# STM32WBA52 register map
File version: 1.3
CPU: CM33 r0p1, little endian, MPU, FPU, 4 interrupt priority bits
Registers are 32-bit, read-write, reset 0x0 unless marked. A register's access mark holds for its fields unless they carry their own. Offsets are from the block's base; [hi:lo] are bit positions; {n}, {i} and the like mark numbered series; 'fields as' and 'values as' point back to an identical list.

## FLASH — Embedded Flash memory
Base 0x40022000
Same registers: SEC_FLASH 0x50022000
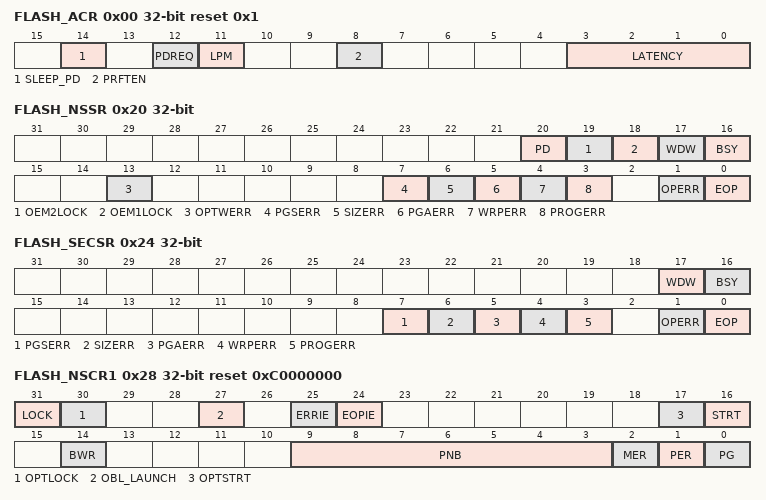
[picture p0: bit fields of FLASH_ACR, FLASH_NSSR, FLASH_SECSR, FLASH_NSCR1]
0x00 FLASH_ACR reset 0x1 — FLASH access control register
  [14] SLEEP_PD — Flash memory power-down mode during Sleep mode This bit determines whether the Flash memory is in power-down mode or Idle mode when the device is in Sleep mode. Access to the bit can be secured by PWR LPMSEC. When secure, a non-secure read/write access is RAZ/WI. It does not generate an illegal access interrupt. This bit can be protected against unprivileged access when secure with FLASH SPRIV or when non-secure with FLASH NSPRIV. The Flash must not be put in power-down while a program or an erase operation is ongoing.
    0=Flash in Idle mode during Sleep mode; 1=Flash in power-down mode during Sleep mode
  [12] PDREQ — Flash power-down mode request This bit requests Flash to enter power-down mode. When Flash enters power-down mode, this bit is cleared by hardware and the PDKEYR is locked. This bit is write-protected with FLASH_PDKEYR. Access to the bit can be secured by PWR LPMSEC. When secure, a non-secure read/write access is RAZ/WI. It does not generate an illegal access interrupt. This bit can be protected against unprivileged access when secure with FLASH SPRIV or when non-secure with FLASH NSPRIV.
    0=No request for Flash to enter power-down mode; 1=Flash requested to enter power-down mode
  [11] LPM — Low-power read mode This bit puts the Flash memory in low-power read mode. Access to the bit can be secured by PWR LPMSEC. When secure, a non-secure read/write access is RAZ/WI. It does not generate an illegal access interrupt. This bit can be protected against unprivileged access when secure with FLASH SPRIV or when non-secure with FLASH NSPRIV. This bit can't be written when a Flash program or erase operation is busy (BSY = 1) or when the write buffer is not empty (WDW = 1). Changing this bit while a Flash program or erase operation is busy (BSY = 1) is rejected.
    0=Flash not in low-power read mode; 1=Flash in low-power read mode
  [8] PRFTEN — Prefetch enable This bit enables the prefetch buffer in the embedded Flash memory. This bit can be protected against unprivileged access by FLASH NSPRIV.
    0=Prefetch disabled; 1=Prefetch enabled
  [3:0] LATENCY — Latency These bits represent the ratio between the AHB hclk1 clock period and the Flash memory access time. Access to the bit can be secured by RCC SYSCLKSEC. When secure, a non-secure read/write access is RAZ/WI. It does not generate an illegal access interrupt. This bit can be protected against unprivileged access when secure with FLASH SPRIV or when non-secure with FLASH NSPRIV. ... Note: Before entering Stop 1 mode software must set FLASH wait state latency to at least 1.
    0=Zero wait state; 1=One wait state; 2=Two wait states; 15=Fifteen wait states
0x08 FLASH_NSKEYR wo — FLASH key register
  [31:0] NSKEY — Flash memory non-secure key The following values must be written consecutively to unlock the FLASH_NSCR1 register, allowing the Flash memory non-secure programming/erasing operations: KEY1: 0x45670123 KEY2: 0xCDEF89AB
0x0C FLASH_SECKEYR wo — FLASH secure key register
  [31:0] SECKEY — Flash memory secure key The following values must be written consecutively to unlock the FLASH_SECCR1 register, allowing the Flash memory secure programming/erasing operations: KEY1: 0x45670123 KEY2: 0xCDEF89AB
0x10 FLASH_OPTKEYR wo — FLASH option key register
  [31:0] OPTKEY — Option byte key The LOCK bit in the FLASH_NSCR1 must be cleared before doing the unlock sequence for OPTLOCK bit. The following values must be written consecutively to unlock the FLASH_NSCR1.OPTSTRT and OBL_LAUNCH register bits concerning user option operations: KEY1: 0x08192A3B KEY2: 0x4C5D6E7F
0x18 FLASH_PDKEYR wo — FLASH power-down key register
  [31:0] PDKEY1 — Flash power-down key The following values must be written consecutively to unlock the PDREQ bit in FLASH_ACR: PDKEY_1: 0x04152637 PDKEY_2: 0xFAFBFCFD
0x20 FLASH_NSSR access per field (reset mask 0xFFF0FFFF) — FLASH status register
  [20] PD ro — Flash in power-down mode This bit indicates that the Flash memory is in power-down state. It is reset when Flash is in normal mode or being awaken.
  [19] OEM2LOCK ro — OEM2 key RDP lock This bit indicates that the OEM2 key read during the OBL is not virgin. When set, the OEM2 key RDP lock mechanism is active.
  [18] OEM1LOCK ro — OEM1 key RDP lock This bit indicates that the OEM1 key read during the OBL is not virgin. When set, the OEM1 key RDP lock mechanism is active.
  [17] WDW ro — Non-secure wait data to write This bit indicates that the Flash memory write buffer has been written by a secure or non-secure operation. It is set when the first data is stored in the buffer and cleared when the write is performed in the Flash memory.
  [16] BSY ro — Non-secure busy This indicates that a Flash memory secure or non-secure operation is in progress. This bit is set at the beginning of a Flash operation and reset when the operation finishes or when an error occurs.
  [13] OPTWERR rw — Option write error This bit is set by hardware when the options bytes are written with an invalid configuration or when modifying options in RDP level 2.. It is cleared by writing 1. Refer to Section7.3.10: Flash memory errors flags for full conditions of error flag setting.
  [7] PGSERR rw — Non-secure programming sequence error This bit is set by hardware when programming sequence is not correct. It is cleared by writing 1. Refer to Section7.3.10: Flash memory errors flags for full conditions of error flag setting.
  [6] SIZERR rw — Non-secure size error This bit is set by hardware when the size of the access is a byte or half-word during a non-secure program sequence. Only quad-word programming is allowed by means of successive word accesses. This bit is cleared by writing 1.
  [5] PGAERR rw — Non-secure programming alignment error This bit is set by hardware when the first word to be programmed is not aligned with a quad-word address, or the second, third or forth word does not belong to the same quad-word address. This bit is cleared by writing 1.
  [4] WRPERR rw — Non-secure write protection error This bit is set by hardware when a non-secure address to be erased/programmed belongs to a write-protected part (by WRP or HDP) of the Flash memory. This bit is cleared by writing 1. Refer to Section7.3.10: Flash memory errors flags for full conditions of error flag setting.
  [3] PROGERR rw — Non-secure programming error This bit is set by hardware when a non-secure quad-word address to be programmed contains a value different from all 1 before programming, except if the data to write is all 0. This bit is cleared by writing 1.
  [1] OPERR rw — Non-secure operation error This bit is set by hardware when a Flash memory non-secure operation (program/erase) completes unsuccessfully. This bit is set only if non-secure error interrupts are enabled (NSERRIE = 1). This bit is cleared by writing 1.
  [0] EOP rw — Non-secure end of operation This bit is set by hardware when one or more Flash memory non-secure operation (program/erase) has been completed successfully. This bit is set only if the non-secure end of operation interrupts are enabled (EOPIE = 1 in FLASH_NSCR1). This bit is cleared by writing1.
0x24 FLASH_SECSR access per field — FLASH secure status register
  [17] WDW ro — Secure wait data to write This bit indicates that the Flash memory write buffer has been written by a secure or non-secure operation. It is set when the first data is stored in the buffer and cleared when the write is performed in the Flash memory.
  [16] BSY ro — Secure busy This bit indicates that a Flash memory secure or non-secure operation is in progress. This is set on the beginning of a Flash operation and reset when the operation finishes or when an error occurs.
  [7] PGSERR rw — Secure programming sequence error This bit is set by hardware when programming sequence is not correct. It is cleared by writing 1. Refer to Section7.3.10: Flash memory errors flags for full conditions of error flag setting.
  [6] SIZERR rw — Secure size error This bit is set by hardware when the size of the access is a byte or half-word during a secure program sequence. Only quad-word programming is allowed by means of successive word accesses.This bit is cleared by writing 1.
  [5] PGAERR rw — Secure programming alignment error This bit is set by hardware when the first word to be programmed is not aligned with a quad-word address, or the second, third or forth word does not belong to the same quad-word address.This bit is cleared by writing 1.
  [4] WRPERR rw — Secure write protection error This bit is set by hardware when an secure address to be erased/programmed belongs to a write-protected part (by WRP or HDP) of the Flash memory. This bit is cleared by writing 1. Refer to Section7.3.10: Flash memory errors flags for full conditions of error flag setting.
  [3] PROGERR rw — Secure programming error This bit is set by hardware when a secure quad-word address to be programmed contains a value different from all 1 before programming, except if the data to write is all 0. This bit is cleared by writing 1.
  [1] OPERR rw — Secure operation error This bit is set by hardware when a Flash memory secure operation (program/erase) completes unsuccessfully. This bit is set only if secure error interrupts are enabled (SECERRIE = 1). This bit is cleared by writing 1.
  [0] EOP rw — Secure end of operation This bit is set by hardware when one or more Flash memory secure operation (program/erase) has been completed successfully. This bit is set only if the secure end of operation interrupts are enabled (EOPIE = 1 in FLASH_SECCR1). This bit is cleared by writing1.
0x28 FLASH_NSCR1 reset 0xC0000000 — FLASH control register
  [31] LOCK — Non-secure lock This bit is set only. When set, the FLASH_NSCR1 register write access is locked. This bit is cleared by hardware after detecting the unlock sequence in FLASH_NSKEYR. In case of an unsuccessful unlock operation, this bit remains set until the next system reset.
  [30] OPTLOCK — Option lock This bit is set only. When set, the FLASH_NSCR1.OPTSRT and OBL_LAUNCH bits concerning user options write access is locked. This bit is cleared by hardware after detecting the unlock sequence in FLASH_OPTKEYR. The FLASH_NSCR1.LOCK bit must be cleared before doing the FLASH_OPTKEYR unlock sequence. In case of an unsuccessful unlock operation, this bit remains set until the next reset.
  [27] OBL_LAUNCH — Force the option byte loading When set to 1, this bit forces the option byte reloading. This bit is cleared only when the option byte loading is complete. This bit is write-protected with OPTLOCK. Note: The LSE oscillator must be disabled, LSEON = 0 and LSERDY = 0, before starting OBL_LAUNCH.
    0=Option byte loading complete; 1=Option byte loading requested
  [25] ERRIE — Non-secure error interrupt enable This bit enables the interrupt generation when the OPERR bit in the FLASH_NSSR is set to 1.
    0=Non-secure OPERR error interrupt disabled; 1=Non-secure OPERR error interrupt enabled
  [24] EOPIE — Non-secure end of operation interrupt enable This bit enables the interrupt generation when the EOP bit in the FLASH_NSSR is set to 1.
    0=Non-secure EOP Interrupt disabled; 1=Non-secure EOP Interrupt enabled
  [17] OPTSTRT — Options modification start This bit triggers an option bytes erase and program operation when set. This bit is write-protected with OPTLOCK.. This bit is set only by software, and is cleared when the BSY bit is cleared in FLASH_NSSR.
  [16] STRT — Non-secure operation start This bit triggers a non-secure erase operation when set. If MER and PER bits are reset and the STRT bit is set, the PGSERR bit in FLASH_NSSR is set (this condition is forbidden). This bit is set only by software and is cleared when the BSY bit is cleared in FLASH_NSSR.
  [14] BWR — Non-secure burst write programming mode When set, this bit selects the burst write programming mode.
  [9:3] PNB — Non-secure page number selection These bits select the page to erase. ... Note that bit 9 is reserved on STM32WBA5xEx devices.
    0=page 0; 1=page 1; 127=page 127
  [2] MER — Non-secure Flash mass erase This bit triggers the Flash non-secure mass erase (all Flash user pages) when set.
  [1] PER — Non-secure page erase
    0=Non-secure page erase disabled; 1=Non-secure page erase enabled
  [0] PG — Non-secure programming
    0=Non-secure Flash programming disabled; 1=Non-secure Flash programming enabled
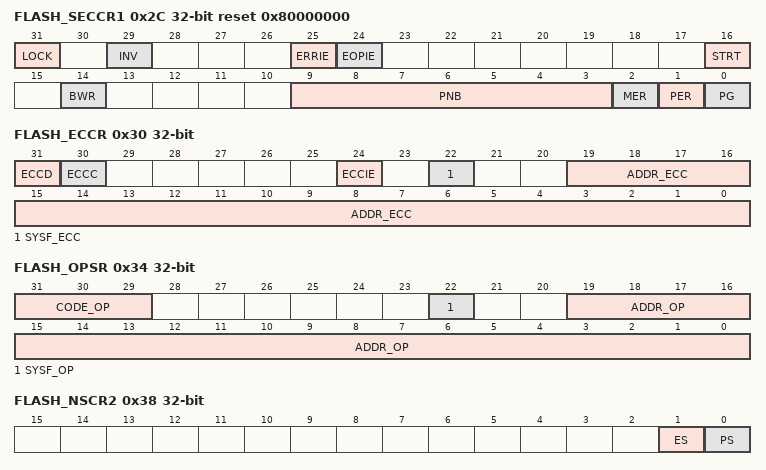
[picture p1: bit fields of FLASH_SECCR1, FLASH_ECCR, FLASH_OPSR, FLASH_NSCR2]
0x2C FLASH_SECCR1 reset 0x80000000 — FLASH secure control register
  [31] LOCK — Secure lock This bit is set only. When set, the FLASH_SECCR1 register is locked. It is cleared by hardware after detecting the unlock sequence in FLASH_SECKEYR register. In case of an unsuccessful unlock operation, this bit remains set until the next system reset.
  [29] INV — Flash memory security state invert This bit inverts the Flash memory security state.
  [25] ERRIE — Secure error interrupt enable This bit enables the interrupt generation when the OPERR bit in FLASH_SECSR is set to 1.
    0=Secure OPERR error interrupt disabled; 1=Secure OPERR error interrupt enabled
  [24] EOPIE — Secure End of operation interrupt enable This bit enables the interrupt generation when the EOP bit in FLASH_SECSR is set to 1.
    0=Secure EOP Interrupt disabled; 1=Secure EOP Interrupt enabled
  [16] STRT — Secure start This bit triggers a secure erase operation when set. If MER and PER bits are reset and the STRT bit is set, the PGSERR in the FLASH_SECSR is set (this condition is forbidden). This bit is set only by software and is cleared when the BSY bit is cleared in FLASH_SECSR.
  [14] BWR — Secure burst write programming mode When set, this bit selects the burst write programming mode.
  [9:3] PNB — Secure page number selection These bits select the page to erase: ... Note that bit 9 is reserved on STM32WBA5xEx devices.
    0=page 0; 1=page 1; 127=page 127
  [2] MER — Secure Flash mass erase This bit triggers the Flash secure mass erase (all Flash user pages) when set.
  [1] PER — Secure page erase
    0=Secure page erase disabled; 1=Secure page erase enabled
  [0] PG — Secure programming
    0=Secure Flash programming disabled; 1=Secure Flash programming enabled
0x30 FLASH_ECCR access per field — FLASH ECC register
  [31] ECCD rw — ECC detection This bit is set by hardware when two ECC errors have been detected (only if ECCC and ECCD were previously cleared). When this bit is set, a NMI is generated. This bit is cleared by writing 1.
  [30] ECCC rw — ECC correction This bit is set by hardware when one ECC error has been detected and corrected (only if ECCC and ECCD were previously cleared). An interrupt is generated if ECCIE is set. This bit is cleared by writing 1.
  [24] ECCIE rw — ECC correction interrupt enable This bit enables the interrupt generation when the ECCC bit in the FLASH_ECCR register is set.
    0=ECCC interrupt disabled; 1=ECCC interrupt enabled
  [22] SYSF_ECC ro — System Flash memory ECC fail This bit indicates that the ECC error correction or double ECC error detection is located in the system Flash memory.
  [19:0] ADDR_ECC ro — ECC fail address This field indicates which address is concerned by the ECC error correction or by the double ECC error detection. The address is given relative to Flash base address, from offset 0x00000 to 0xFFFF0. Note that bit 19 is reserved on STM32WBAxEx devices.
0x34 FLASH_OPSR ro (reset mask 0xF000000) — FLASH operation status register
  [31:29] CODE_OP — Flash memory operation code This field indicates which Flash memory operation has been interrupted by a system reset:
    0=No Flash operation interrupted by previous reset; 1=Single write operation interrupted; 2=Burst write operation interrupted; 3=Page erase operation interrupted; 5=Mass erase operation interrupted; 6=Option change operation interrupted
  [22] SYSF_OP — Operation in system Flash memory interrupted This bit indicates that the reset occurred during an operation in the system Flash memory.
  [19:0] ADDR_OP — Interrupted operation address This field indicates which address in the Flash memory was accessed when reset occurred. The address is given relative to the Flash base address, from offset 0x00000 to 0xFFFF0. Note that bit 19 is reserved on STM32WBAxEx devices.
0x38 FLASH_NSCR2 — FLASH control 2 register
  [1] ES — Erase suspend request
    0=erase suspend disabled; 1=erase suspend requested (enabled)
  [0] PS — Program suspend request
    0=program suspend disabled; 1=program suspend requested (enabled)
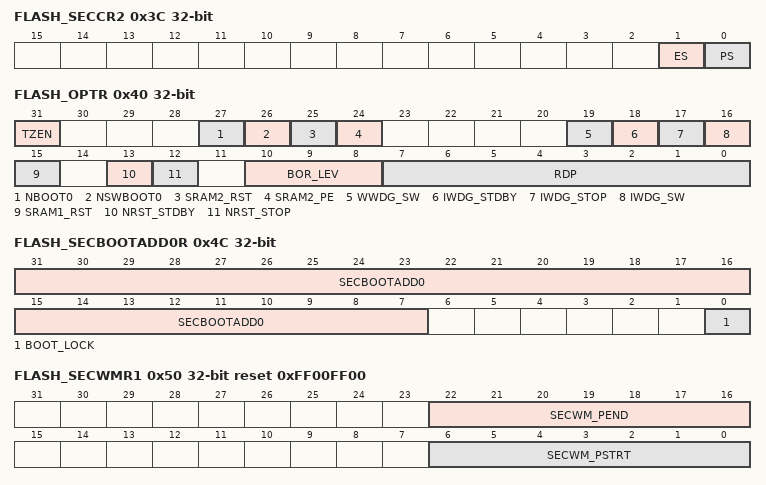
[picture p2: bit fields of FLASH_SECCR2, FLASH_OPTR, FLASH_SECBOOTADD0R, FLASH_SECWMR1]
0x3C FLASH_SECCR2 — FLASH secure control 2 register
  fields as FLASH_NSCR2
0x40 FLASH_OPTR reset not defined — FLASH option register
  [31] TZEN — Global TrustZone security enable
    0=Global TrustZone security disabled; 1=Global TrustZone security enabled
  [27] NBOOT0 — NBOOT0 option bit
    0=NBOOT0 = 0; 1=NBOOT0 = 1
  [26] NSWBOOT0 — Software BOOT0
    0=BOOT0 taken from the option bit NBOOT0; 1=BOOT0 taken from PH3/BOOT0 pin
  [25] SRAM2_RST — SRAM2 erase when system reset
    0=SRAM2 erased when a system reset occurs; 1=SRAM2 not erased when a system reset occurs
  [24] SRAM2_PE — SRAM2 parity check enable
    0=SRAM2 parity check enabled; 1=SRAM2 parity check disabled
  [19] WWDG_SW — Window watchdog selection
    0=Hardware window watchdog selected; 1=Software window watchdog selected
  [18] IWDG_STDBY — Independent watchdog counter freeze in Standby mode
    0=Independent watchdog counter frozen in Standby mode; 1=Independent watchdog counter running in Standby mode
  [17] IWDG_STOP — Independent watchdog counter freeze in Stop mode
    0=Independent watchdog counter frozen in Stop mode; 1=Independent watchdog counter running in Stop mode
  [16] IWDG_SW — Independent watchdog enable selection
    0=Hardware mode, independent watchdog started automatically be hardware on reset selected; 1=Software mode, independent watchdog started by software command selected
  [15] SRAM1_RST — SRAM1 erase upon system reset
    0=SRAM1erased when a system reset occurs; 1=SRAM1 not erased when a system reset occurs
  [13] NRST_STDBY — Reset generation in Standby mode
    0=Reset generated when entering the Standby mode; 1=No reset generated when entering the Standby mode
  [12] NRST_STOP — Reset generation in Stop mode
    0=Reset generated when entering the Stop mode; 1=No reset generated when entering the Stop mode
  [10:8] BOR_LEV — BOR reset level These bits contain the VsubDD/sub supply level threshold that activates/releases the reset.
    0=BOR level 0 (reset level threshold around 1.7V); 1=BOR level 1 (reset level threshold around 2.0V); 2=BOR level 2 (reset level threshold around 2.2V); 3=BOR level 3 (reset level threshold around 2.5V); 4=BOR level 4 (reset level threshold around 2.8V)
  [7:0] RDP — Readout protection level Others: Level 1 (memories readout protection active) Note: Refer to Section7.6.2: Readout protection (RDP) for more details.
    170=Level 0 (readout protection not active); 85=Level 0.5 (readout protection not active, only non-secure debug access is possible). Only available when TrustZone is active (TZEN=1); 204=Level 2 (chip readout protection active)
0x44 FLASH_NSBOOTADD0R reset 0xF (reset mask 0xF) — FLASH boot address 0 register
  [31:7] NSBOOTADD0 — Non-secure boot base address 0 This address is only used when TZEN = 0. The non-secure boot memory address can be programmed to any address in the valid address range (see Table 28: Boot space versus RDP protection) with a granularity of 128 bytes. These bits correspond to address [31:7]. The NSBOOTADD0 option bytes are selected following the BOOT0 pin or NSWBOOT0 state. Examples: NSBOOTADD0[24:0] = 0x0100000: Boot from Flash memory (0x0800 0000) NSBOOTADD0[24:0] = 0x017F100: Boot from system memory bootloader (0x0BF8 8000) NSBOOTADD0[24:0] = 0x0400200: Boot from SRAM2 on S-Bus (0x2001 0000)
0x48 FLASH_NSBOOTADD1R reset 0xF (reset mask 0xF) — FLASH boot address 1 register
  [31:7] NSBOOTADD1 — Non-secure boot address 1 This address is only used when TZEN = 0. The non-secure boot memory address can be programmed to any address in the valid address range (see Table 28: Boot space versus RDP protection) with a granularity of 128 bytes. These bits correspond to address [31:7]. The NSBOOTADD0 option bytes are selected following the BOOT0 pin or NSWBOOT0 state. Examples: NSBOOTADD1[24:0] = 0x0100000: Boot from Flash memory (0x0800 0000) NSBOOTADD1[24:0] = 0x017F100: Boot from system memory bootloader (0x0BF8 8000) NSBOOTADD1[24:0] = 0x0400200: Boot from SRAM2 (0x2001 0000)
0x4C FLASH_SECBOOTADD0R reset not defined — FLASH secure boot address 0 register
  [31:7] SECBOOTADD0 — Secure boot base address 0 This address is only used when TZEN = 1. The secure boot memory address can be programmed to any address in the valid address range (see Table28: Boot space versus RDP protection) with a granularity of 128 bytes. This bits correspond to address [31:7] The SECBOOTADD0 option bytes are selected following the BOOT0 pin or NSWBOOT0 state. Examples: SECBOOTADD0[24:0] = 0x018 0000: Boot from secure user Flash memory (0x0C00 0000) SECBOOTADD0[24:0] = 0x01F F000: Boot from RSS system Flash memory (0x0FF8 0000) SECBOOTADD0[24:0] = 0x060 0000: Boot from secure SRAM1 on S-Bus (0x3000 0000)
  [0] BOOT_LOCK — Boot lock This lock is only used when TZEN = 0. When set, the boot is always forced to base address value programmed in SECBOOTADD0[24:0] option bytes whatever the boot selection option. When set, this bit can only be cleared by an RDP regression level 1 to level 0.
0x50 FLASH_SECWMR1 reset 0xFF00FF00 (reset mask 0xFF00FF00) — FLASH secure watermark register 1
  [22:16] SECWM_PEND — End page of secure area This field contains the last page of the secure area.
  [6:0] SECWM_PSTRT — Start page of secure area This field contains the first page of the secure area.
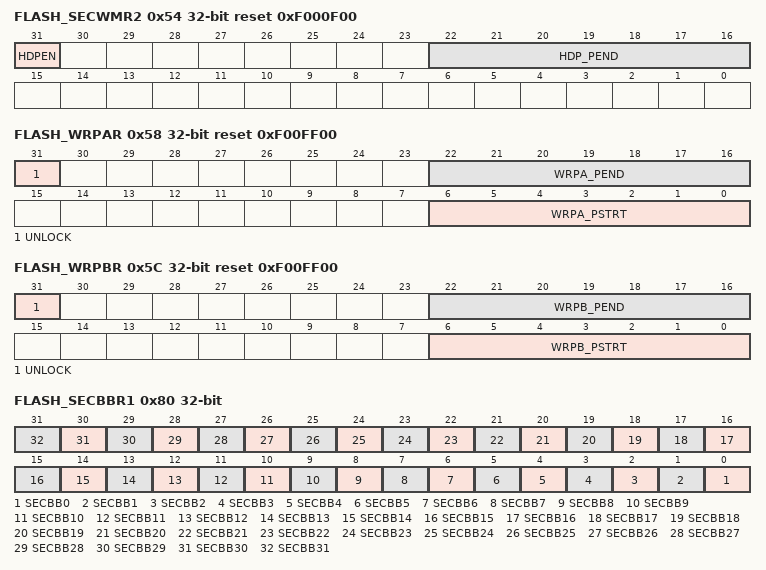
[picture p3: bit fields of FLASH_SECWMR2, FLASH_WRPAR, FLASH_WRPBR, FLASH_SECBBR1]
0x54 FLASH_SECWMR2 reset 0xF000F00 (reset mask 0xF000F00) — FLASH secure watermark register 2
  [31] HDPEN — Secure Hide protection area enable
    0=No secure HDP area; 1=Secure HDP area enabled
  [22:16] HDP_PEND — End page of secure hide protection area This field contains the last page of the secure HDP area.
0x58 FLASH_WRPAR reset 0xF00FF00 (reset mask 0xF00FF00) — FLASH WRP area A address register
  [31] UNLOCK — WPR area A unlock
    0=WRPA start and end pages locked; 1=WRPA start and end pages unlocked
  [22:16] WRPA_PEND — WPR area A end page This field contains the last page of the WPR area A. Note that bit 22 is reserved on STM32WBAxEx devices.
  [6:0] WRPA_PSTRT — WPR area A start page This field contains the first page of the WPR area A. Note that bit 6 is reserved on STM32WBAxEx devices.
0x5C FLASH_WRPBR reset 0xF00FF00 (reset mask 0xF00FF00) — FLASH WRP area B address register
  [31] UNLOCK — WPR area B unlock
    0=WRPB start and end pages locked; 1=WRPB start and end pages unlocked
  [22:16] WRPB_PEND — WRP area B end page This field contains the last page of the WRP area B. Note that bit 22 is reserved on STM32WBAxEx devices.
  [6:0] WRPB_PSTRT — WRP area B start page This field contains the first page of the WRP area B. Note that bit 6 is reserved on STM32WBAxEx devices.
0x70 FLASH_OEM1KEYR1 wo — FLASH OEM1 key register 1
  [31:0] OEM1KEY — OEM1 key least significant bytes
0x74 FLASH_OEM1KEYR2 wo — FLASH OEM1 key register 2
  [31:0] OEM1KEY — OEM1 key most significant bytes
0x78 FLASH_OEM2KEYR1 wo — FLASH OEM2 key register 1
  [31:0] OEM2KEY — OEM2 key least significant bytes
0x7C FLASH_OEM2KEYR2 wo — FLASH OEM2 key register 2
  [31:0] OEM2KEY — OEM2 key most significant bytes
0x80 FLASH_SECBBR1 — FLASH secure block based register 1
  [all] fields
    0=Page (32 x (x - 1) + y) in Flash not block-based secure; 1=Page (32 x (x - 1) + y) in Flash block-based secure
  [n] SECBB{n} (n=0..31) — page secure/non-secure attribution Each bit is used to set one page security attribution.
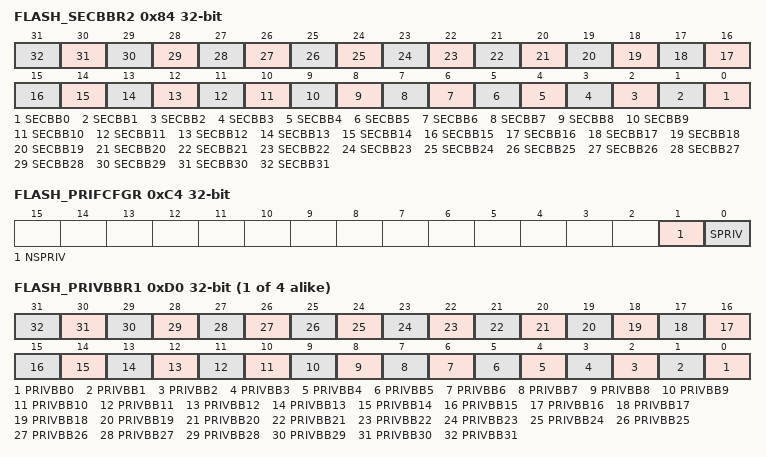
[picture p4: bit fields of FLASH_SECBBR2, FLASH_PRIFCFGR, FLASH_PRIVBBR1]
0x84 FLASH_SECBBR2 — FLASH secure block based register 2
  fields as FLASH_SECBBR1
0xC0 FLASH_SECHDPCR — FLASH secure HDP control register
  [0] HDP_ACCDIS — Secure HDP area access disable When set, this bit is only cleared by a system reset.
    0=Access to secure HDP area granted; 1=Access to secure HDP area denied (SECWMRx option bytes modification blocked, refer to Rules for modifying specific option bytes)
0xC4 FLASH_PRIFCFGR — FLASH privilege configuration register
  [1] NSPRIV — Privileged protection for non-secure registers
    0=Non-secure Flash registers can be read and written by privileged or unprivileged access; 1=Non-secure Flash registers can be read and written by privileged access only
  [0] SPRIV — Privileged protection for secure registers This bit is secure write protected. It can only be written by a secure privileged access when TrustZone is enabled (TZEN=1).
    0=Secure Flash registers can be read and written by privileged or unprivileged access; 1=Secure Flash registers can be read and written by privileged access only
{0xCC+4i} FLASH_PRIVBBR{i} (i=1..4) — FLASH privilege block based register {i}
  [all] fields
    0=Page (32 x (x - 1) + y) in Flash accessible by unprivileged access; 1=Page (32 x (x - 1) + y) in Flash only accessible by privileged access
  [n] PRIVBB{n} (n=0..31) — page privileged/unprivileged attribution Each bit is used to set one page privilege attribution in Flash.

## Notices in the file
Copyright (c) 2025 STMicroelectronics.
SPDX-License-Identifier: Apache-2.0
Licensed under the Apache License, Version 2.0 (the "License");
you may not use this file except in compliance with the License.
You may obtain a copy of the License at
http://www.apache.org/licenses/LICENSE-2.0
Unless required by applicable law or agreed to in writing, software
distributed under the License is distributed on an "AS IS" BASIS,
WITHOUT WARRANTIES OR CONDITIONS OF ANY KIND, either express or implied.
See the License for the specific language governing permissions and
limitations under the License.
